# LM3S101 register map
File version: 7944
Registers are 32-bit, read-write, no defined reset value unless marked. A register's access mark holds for its fields unless they carry their own. Offsets are from the block's base; [hi:lo] are bit positions; <NAME> marks a mode.

## UART0 — Register map for UART0 peripheral
Base 0x4000C000; register names take the prefix UART0
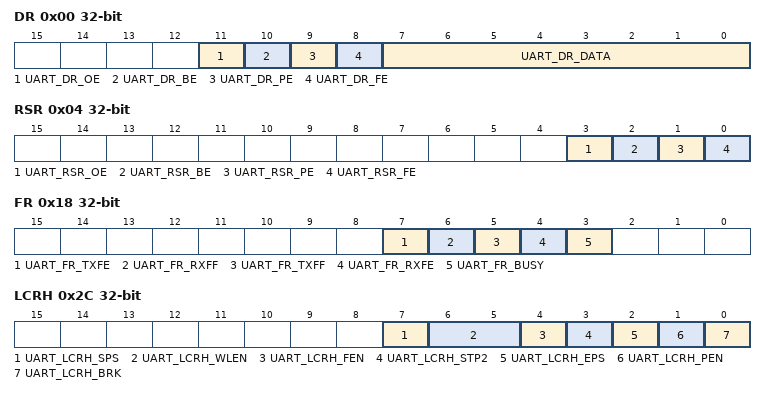
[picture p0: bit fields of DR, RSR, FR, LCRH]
0x00 DR — UART Data
  [11] UART_DR_OE — UART Overrun Error
  [10] UART_DR_BE — UART Break Error
  [9] UART_DR_PE — UART Parity Error
  [8] UART_DR_FE — UART Framing Error
  [7:0] UART_DR_DATA — Data Transmitted or Received
0x04 RSR — UART Receive Status/Error Clear
  [3] UART_RSR_OE — UART Overrun Error
  [2] UART_RSR_BE — UART Break Error
  [1] UART_RSR_PE — UART Parity Error
  [0] UART_RSR_FE — UART Framing Error
0x04 ECR (UART_ALT view) — UART Receive Status/Error Clear
  [7:0] UART_ECR_DATA — Error Clear
0x18 FR — UART Flag
  [7] UART_FR_TXFE — UART Transmit FIFO Empty
  [6] UART_FR_RXFF — UART Receive FIFO Full
  [5] UART_FR_TXFF — UART Transmit FIFO Full
  [4] UART_FR_RXFE — UART Receive FIFO Empty
  [3] UART_FR_BUSY — UART Busy
0x24 IBRD — UART Integer Baud-Rate Divisor
  [15:0] UART_IBRD_DIVINT — Integer Baud-Rate Divisor
0x28 FBRD — UART Fractional Baud-Rate Divisor
  [5:0] UART_FBRD_DIVFRAC — Fractional Baud-Rate Divisor
0x2C LCRH — UART Line Control
  [7] UART_LCRH_SPS — UART Stick Parity Select
  [6:5] UART_LCRH_WLEN — UART Word Length
    0=5 bits (default); 1=6 bits; 2=7 bits; 3=8 bits
  [4] UART_LCRH_FEN — UART Enable FIFOs
  [3] UART_LCRH_STP2 — UART Two Stop Bits Select
  [2] UART_LCRH_EPS — UART Even Parity Select
  [1] UART_LCRH_PEN — UART Parity Enable
  [0] UART_LCRH_BRK — UART Send Break
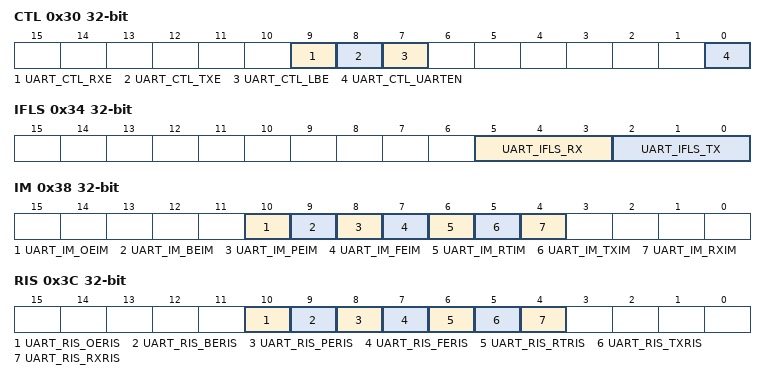
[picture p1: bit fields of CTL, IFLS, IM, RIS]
0x30 CTL — UART Control
  [9] UART_CTL_RXE — UART Receive Enable
  [8] UART_CTL_TXE — UART Transmit Enable
  [7] UART_CTL_LBE — UART Loop Back Enable
  [0] UART_CTL_UARTEN — UART Enable
0x34 IFLS — UART Interrupt FIFO Level Select
  [5:3] UART_IFLS_RX — UART Receive Interrupt FIFO Level Select
    0=UART_IFLS_RX1_8 (RX FIFO >= 1/8 full); 1=UART_IFLS_RX2_8 (RX FIFO >= 1/4 full); 2=UART_IFLS_RX4_8 (RX FIFO >= 1/2 full (default)); 3=UART_IFLS_RX6_8 (RX FIFO >= 3/4 full); 4=UART_IFLS_RX7_8 (RX FIFO >= 7/8 full)
  [2:0] UART_IFLS_TX — UART Transmit Interrupt FIFO Level Select
    0=UART_IFLS_TX1_8 (TX FIFO <= 1/8 full); 1=UART_IFLS_TX2_8 (TX FIFO <= 1/4 full); 2=UART_IFLS_TX4_8 (TX FIFO <= 1/2 full (default)); 3=UART_IFLS_TX6_8 (TX FIFO <= 3/4 full); 4=UART_IFLS_TX7_8 (TX FIFO <= 7/8 full)
0x38 IM — UART Interrupt Mask
  [10] UART_IM_OEIM — UART Overrun Error Interrupt Mask
  [9] UART_IM_BEIM — UART Break Error Interrupt Mask
  [8] UART_IM_PEIM — UART Parity Error Interrupt Mask
  [7] UART_IM_FEIM — UART Framing Error Interrupt Mask
  [6] UART_IM_RTIM — UART Receive Time-Out Interrupt Mask
  [5] UART_IM_TXIM — UART Transmit Interrupt Mask
  [4] UART_IM_RXIM — UART Receive Interrupt Mask
0x3C RIS — UART Raw Interrupt Status
  [10] UART_RIS_OERIS — UART Overrun Error Raw Interrupt Status
  [9] UART_RIS_BERIS — UART Break Error Raw Interrupt Status
  [8] UART_RIS_PERIS — UART Parity Error Raw Interrupt Status
  [7] UART_RIS_FERIS — UART Framing Error Raw Interrupt Status
  [6] UART_RIS_RTRIS — UART Receive Time-Out Raw Interrupt Status
  [5] UART_RIS_TXRIS — UART Transmit Raw Interrupt Status
  [4] UART_RIS_RXRIS — UART Receive Raw Interrupt Status
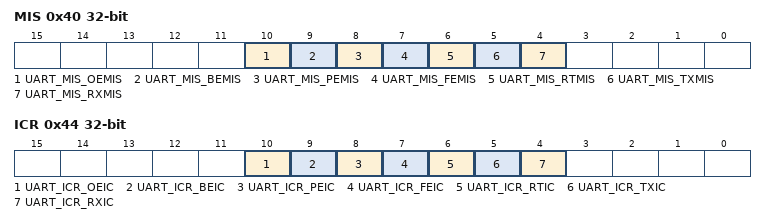
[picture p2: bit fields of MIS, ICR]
0x40 MIS — UART Masked Interrupt Status
  [10] UART_MIS_OEMIS — UART Overrun Error Masked Interrupt Status
  [9] UART_MIS_BEMIS — UART Break Error Masked Interrupt Status
  [8] UART_MIS_PEMIS — UART Parity Error Masked Interrupt Status
  [7] UART_MIS_FEMIS — UART Framing Error Masked Interrupt Status
  [6] UART_MIS_RTMIS — UART Receive Time-Out Masked Interrupt Status
  [5] UART_MIS_TXMIS — UART Transmit Masked Interrupt Status
  [4] UART_MIS_RXMIS — UART Receive Masked Interrupt Status
0x44 ICR wo — UART Interrupt Clear
  [10] UART_ICR_OEIC — Overrun Error Interrupt Clear
  [9] UART_ICR_BEIC — Break Error Interrupt Clear
  [8] UART_ICR_PEIC — Parity Error Interrupt Clear
  [7] UART_ICR_FEIC — Framing Error Interrupt Clear
  [6] UART_ICR_RTIC — Receive Time-Out Interrupt Clear
  [5] UART_ICR_TXIC — Transmit Interrupt Clear
  [4] UART_ICR_RXIC — Receive Interrupt Clear

## COMP — Register map for COMP peripheral
Base 0x4003C000; register names take the prefix COMP
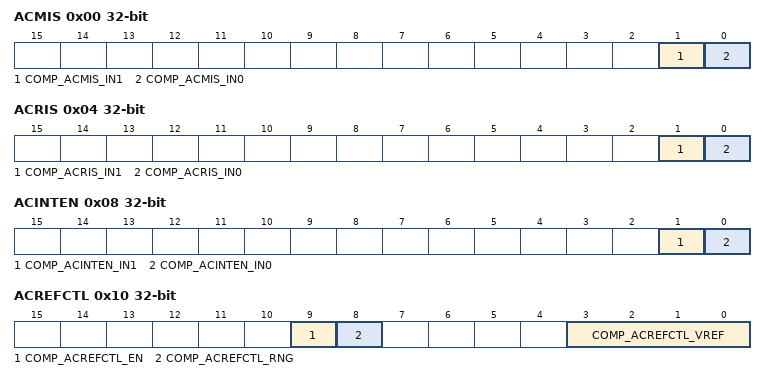
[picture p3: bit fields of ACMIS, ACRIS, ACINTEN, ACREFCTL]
0x00 ACMIS — Analog Comparator Masked Interrupt Status
  [1] COMP_ACMIS_IN1 — Comparator 1 Masked Interrupt Status
  [0] COMP_ACMIS_IN0 — Comparator 0 Masked Interrupt Status
0x04 ACRIS — Analog Comparator Raw Interrupt Status
  [1] COMP_ACRIS_IN1 — Comparator 1 Interrupt Status
  [0] COMP_ACRIS_IN0 — Comparator 0 Interrupt Status
0x08 ACINTEN — Analog Comparator Interrupt Enable
  [1] COMP_ACINTEN_IN1 — Comparator 1 Interrupt Enable
  [0] COMP_ACINTEN_IN0 — Comparator 0 Interrupt Enable
0x10 ACREFCTL — Analog Comparator Reference Voltage Control
  [9] COMP_ACREFCTL_EN — Resistor Ladder Enable
  [8] COMP_ACREFCTL_RNG — Resistor Ladder Range
  [3:0] COMP_ACREFCTL_VREF — Resistor Ladder Voltage Ref
0x20 ACSTAT0 — Analog Comparator Status 0
  [1] COMP_ACSTAT0_OVAL — Comparator Output Value
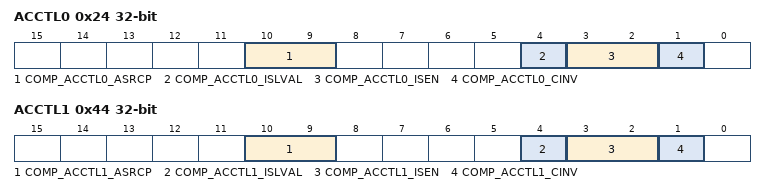
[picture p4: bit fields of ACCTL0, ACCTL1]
0x24 ACCTL0 — Analog Comparator Control 0
  [10:9] COMP_ACCTL0_ASRCP — Analog Source Positive
    0=COMP_ACCTL0_ASRCP_PIN (Pin value of Cn+); 1=COMP_ACCTL0_ASRCP_PIN0 (Pin value of C0+); 2=COMP_ACCTL0_ASRCP_REF (Internal voltage reference (VIREF))
  [4] COMP_ACCTL0_ISLVAL — Interrupt Sense Level Value
  [3:2] COMP_ACCTL0_ISEN — Interrupt Sense
    0=COMP_ACCTL0_ISEN_LEVEL (Level sense, see ISLVAL); 1=COMP_ACCTL0_ISEN_FALL (Falling edge); 2=COMP_ACCTL0_ISEN_RISE (Rising edge); 3=COMP_ACCTL0_ISEN_BOTH (Either edge)
  [1] COMP_ACCTL0_CINV — Comparator Output Invert
0x40 ACSTAT1 — Analog Comparator Status 1
  [1] COMP_ACSTAT1_OVAL — Comparator Output Value
0x44 ACCTL1 — Analog Comparator Control 1
  [10:9] COMP_ACCTL1_ASRCP — Analog Source Positive
    0=COMP_ACCTL1_ASRCP_PIN (Pin value of Cn+); 1=COMP_ACCTL1_ASRCP_PIN0 (Pin value of C0+); 2=COMP_ACCTL1_ASRCP_REF (Internal voltage reference (VIREF))
  [4] COMP_ACCTL1_ISLVAL — Interrupt Sense Level Value
  [3:2] COMP_ACCTL1_ISEN — Interrupt Sense
    0=COMP_ACCTL1_ISEN_LEVEL (Level sense, see ISLVAL); 1=COMP_ACCTL1_ISEN_FALL (Falling edge); 2=COMP_ACCTL1_ISEN_RISE (Rising edge); 3=COMP_ACCTL1_ISEN_BOTH (Either edge)
  [1] COMP_ACCTL1_CINV — Comparator Output Invert

## FLASH_CTRL — Register map for FLASH_CTRL peripheral
Base 0x400FD000; register names take the prefix FLASH_CTRL
0x00 FMA — Flash Memory Address
  [12:0] FLASH_FMA_OFFSET — Address Offset
0x04 FMD — Flash Memory Data
  [31:0] FLASH_FMD_DATA — Data Value
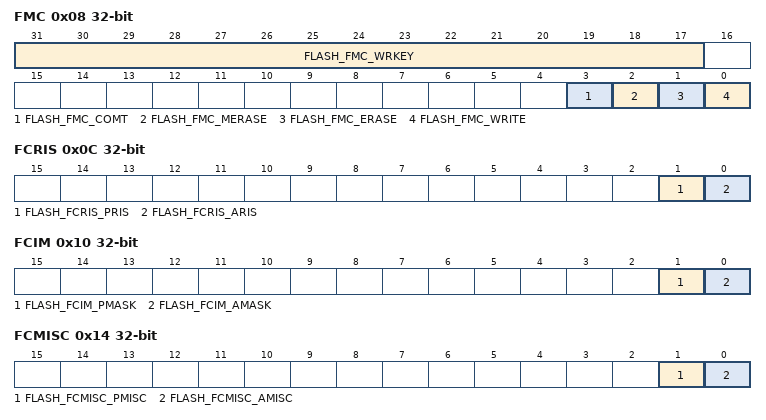
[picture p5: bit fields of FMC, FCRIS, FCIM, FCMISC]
0x08 FMC — Flash Memory Control
  [31:17] FLASH_FMC_WRKEY — FLASH write key
  [3] FLASH_FMC_COMT — Commit Register Value
  [2] FLASH_FMC_MERASE — Mass Erase Flash Memory
  [1] FLASH_FMC_ERASE — Erase a Page of Flash Memory
  [0] FLASH_FMC_WRITE — Write a Word into Flash Memory
0x0C FCRIS — Flash Controller Raw Interrupt Status
  [1] FLASH_FCRIS_PRIS — Programming Raw Interrupt Status
  [0] FLASH_FCRIS_ARIS — Access Raw Interrupt Status
0x10 FCIM — Flash Controller Interrupt Mask
  [1] FLASH_FCIM_PMASK — Programming Interrupt Mask
  [0] FLASH_FCIM_AMASK — Access Interrupt Mask
0x14 FCMISC — Flash Controller Masked Interrupt Status and Clear
  [1] FLASH_FCMISC_PMISC — Programming Masked Interrupt Status and Clear
  [0] FLASH_FCMISC_AMISC — Access Masked Interrupt Status and Clear
0x1130 FMPRE — Flash Memory Protection Read Enable
0x1134 FMPPE — Flash Memory Protection Program Enable
0x1140 USECRL — USec Reload
  [7:0] FLASH_USECRL — Microsecond Reload Value
